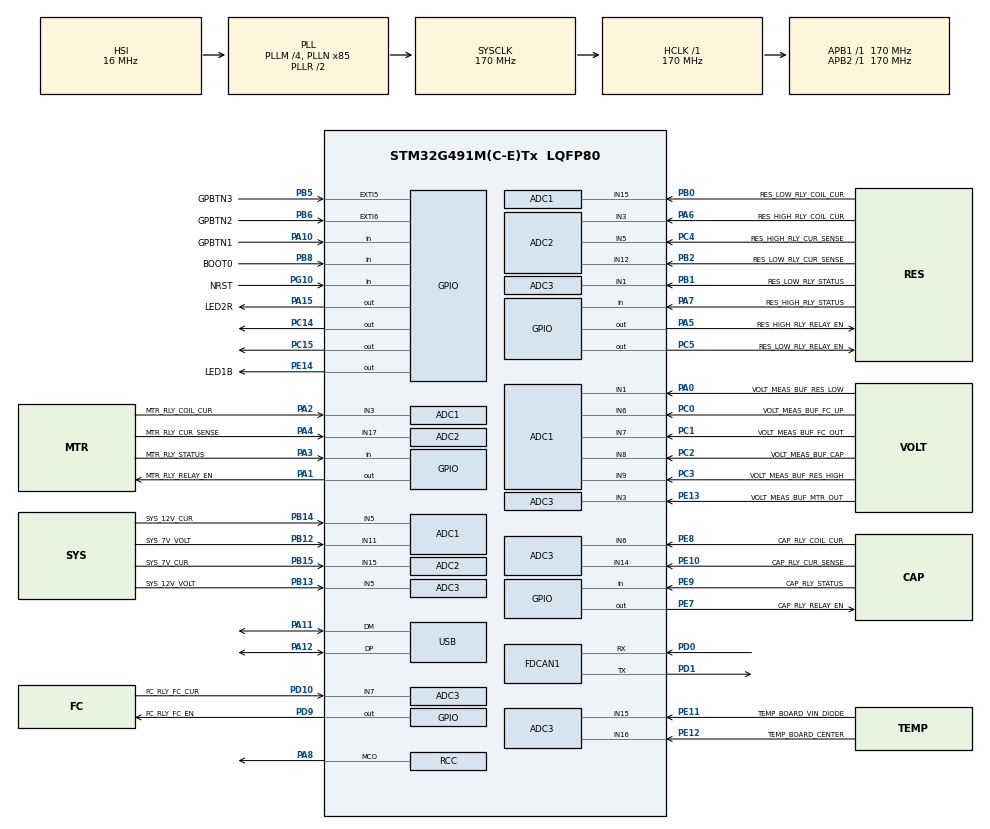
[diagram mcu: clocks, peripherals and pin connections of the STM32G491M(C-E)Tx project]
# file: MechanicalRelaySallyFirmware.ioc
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ADC1.Channel-0\#ChannelRegularConversion=ADC_CHANNEL_3
ADC1.NbrOfConversionFlag=1
ADC1.OffsetNumber-0\#ChannelRegularConversion=ADC_OFFSET_NONE
ADC1.Rank-0\#ChannelRegularConversion=1
ADC1.SamplingTime-0\#ChannelRegularConversion=ADC_SAMPLETIME_2CYCLES_5
ADC1.master=1
ADC2.Channel-0\#ChannelRegularConversion=ADC_CHANNEL_17
ADC2.NbrOfConversionFlag=1
ADC2.OffsetNumber-0\#ChannelRegularConversion=ADC_OFFSET_NONE
ADC2.Rank-0\#ChannelRegularConversion=1
ADC2.SamplingTime-0\#ChannelRegularConversion=ADC_SAMPLETIME_2CYCLES_5
ADC3.Channel-0\#ChannelRegularConversion=ADC_CHANNEL_1
ADC3.NbrOfConversionFlag=1
ADC3.OffsetNumber-0\#ChannelRegularConversion=ADC_OFFSET_NONE
ADC3.Rank-0\#ChannelRegularConversion=1
ADC3.SamplingTime-0\#ChannelRegularConversion=ADC_SAMPLETIME_2CYCLES_5
ADC3.master=1
FDCAN1.CalculateBaudRateNominal=3541666
FDCAN1.CalculateTimeBitNominal=282
FDCAN1.CalculateTimeQuantumNominal=94.11764705882354
Mcu.Family=STM32G4
Mcu.Name=STM32G491M(C-E)Tx
Mcu.Package=LQFP80
NVIC.PriorityGroup=NVIC_PRIORITYGROUP_4
NVIC.TIM7_IRQn=true\:15\:0\:false\:false\:true\:false\:true\:true
NVIC.TimeBase=TIM7_IRQn
NVIC.TimeBaseIP=TIM7
PA0.GPIO_Label=VOLT_MEAS_BUF_RES_LOW
PA0.Mode=IN1-Single-Ended
PA0.Signal=ADC1_IN1
PA1.GPIO_Label=MTR_RLY_RELAY_EN
PA1.Signal=GPIO_Output
PA10.GPIO_Label=GPBTN1
PA10.Signal=GPIO_Input
PA11.Mode=Device
PA11.Signal=USB_DM
PA12.Mode=Device
PA12.Signal=USB_DP
PA13.Mode=Serial_Wire
PA13.Signal=SYS_JTMS-SWDIO
PA14.Mode=Serial_Wire
PA14.Signal=SYS_JTCK-SWCLK
PA15.GPIO_Label=LED2R
PA15.Signal=GPIO_Output
PA2.GPIO_Label=MTR_RLY_COIL_CUR
PA2.Mode=IN3-Single-Ended
PA2.Signal=ADC1_IN3
PA3.GPIO_Label=MTR_RLY_STATUS
PA3.Signal=GPIO_Input
PA4.GPIO_Label=MTR_RLY_CUR_SENSE
PA4.Mode=IN17-Single-Ended
PA4.Signal=ADC2_IN17
PA5.GPIO_Label=RES_HIGH_RLY_RELAY_EN
PA5.Signal=GPIO_Output
PA6.GPIO_Label=RES_HIGH_RLY_COIL_CUR
PA6.Mode=IN3-Single-Ended
PA6.Signal=ADC2_IN3
PA7.GPIO_Label=RES_HIGH_RLY_STATUS
PA7.Signal=GPIO_Input
PA8.Mode=Clock-out
PA8.Signal=RCC_MCO
PB0.GPIO_Label=RES_LOW_RLY_COIL_CUR
PB0.Mode=IN15-Single-Ended
PB0.Signal=ADC1_IN15
PB1.GPIO_Label=RES_LOW_RLY_STATUS
PB1.Mode=IN1-Single-Ended
PB1.Signal=ADC3_IN1
PB12.GPIO_Label=SYS_7V_VOLT
PB12.Mode=IN11-Single-Ended
PB12.Signal=ADC1_IN11
PB13.GPIO_Label=SYS_12V_VOLT
PB13.Mode=IN5-Single-Ended
PB13.Signal=ADC3_IN5
PB14.GPIO_Label=SYS_12V_CUR
PB14.Mode=IN5-Single-Ended
PB14.Signal=ADC1_IN5
PB15.GPIO_Label=SYS_7V_CUR
PB15.Mode=IN15-Single-Ended
PB15.Signal=ADC2_IN15
PB2.GPIO_Label=RES_LOW_RLY_CUR_SENSE
PB2.Mode=IN12-Single-Ended
PB2.Signal=ADC2_IN12
PB5.GPIO_Label=GPBTN3
PB5.Signal=GPXTI5
PB6.GPIO_Label=GPBTN2
PB6.Signal=GPXTI6
PB8-BOOT0.GPIO_Label=BOOT0
PB8-BOOT0.Signal=GPIO_Input
PC0.GPIO_Label=VOLT_MEAS_BUF_FC_UP
PC0.Mode=IN6-Single-Ended
PC0.Signal=ADC1_IN6
PC1.GPIO_Label=VOLT_MEAS_BUF_FC_OUT
PC1.Mode=IN7-Single-Ended
PC1.Signal=ADC1_IN7
PC14-OSC32_IN.Signal=GPIO_Output
PC15-OSC32_OUT.Signal=GPIO_Output
PC2.GPIO_Label=VOLT_MEAS_BUF_CAP
PC2.Mode=IN8-Single-Ended
PC2.Signal=ADC1_IN8
PC3.GPIO_Label=VOLT_MEAS_BUF_RES_HIGH
PC3.Mode=IN9-Single-Ended
PC3.Signal=ADC1_IN9
PC4.GPIO_Label=RES_HIGH_RLY_CUR_SENSE
PC4.Mode=IN5-Single-Ended
PC4.Signal=ADC2_IN5
PC5.GPIO_Label=RES_LOW_RLY_RELAY_EN
PC5.Signal=GPIO_Output
PD0.Mode=FDCAN_Activate
PD0.Signal=FDCAN1_RX
PD1.Mode=FDCAN_Activate
PD1.Signal=FDCAN1_TX
PD10.GPIO_Label=FC_RLY_FC_CUR
PD10.Mode=IN7-Single-Ended
PD10.Signal=ADC3_IN7
PD9.GPIO_Label=FC_RLY_FC_EN
PD9.Signal=GPIO_Output
PE10.GPIO_Label=CAP_RLY_CUR_SENSE
PE10.Mode=IN14-Single-Ended
PE10.Signal=ADC3_IN14
PE11.GPIO_Label=TEMP_BOARD_VIN_DIODE
PE11.Mode=IN15-Single-Ended
PE11.Signal=ADC3_IN15
PE12.GPIO_Label=TEMP_BOARD_CENTER
PE12.Mode=IN16-Single-Ended
PE12.Signal=ADC3_IN16
PE13.GPIO_Label=VOLT_MEAS_BUF_MTR_OUT
PE13.Mode=IN3-Single-Ended
PE13.Signal=ADC3_IN3
PE14.GPIO_Label=LED1B
PE14.Signal=GPIO_Output
PE7.GPIO_Label=CAP_RLY_RELAY_EN
PE7.Signal=GPIO_Output
PE8.GPIO_Label=CAP_RLY_COIL_CUR
PE8.Mode=IN6-Single-Ended
PE8.Signal=ADC3_IN6
PE9.GPIO_Label=CAP_RLY_STATUS
PE9.Signal=GPIO_Input
PF0-OSC_IN.Mode=HSE-External-Clock-Source
PF0-OSC_IN.Signal=RCC_OSC_IN
PG10-NRST.GPIO_Label=NRST
PG10-NRST.Signal=GPIO_Input
ProjectManager.HeapSize=0x200
ProjectManager.StackSize=0x400
ProjectManager.TargetToolchain=STM32CubeIDE
RCC.ADC12Freq_Value=170000000
RCC.ADC345Freq_Value=170000000
RCC.AHBFreq_Value=170000000
RCC.APB1Freq_Value=170000000
RCC.APB1TimFreq_Value=170000000
RCC.APB2Freq_Value=170000000
RCC.APB2TimFreq_Value=170000000
RCC.CortexFreq_Value=170000000
RCC.EXTERNAL_CLOCK_VALUE=12288000
RCC.HCLKFreq_Value=170000000
RCC.HSE_VALUE=8000000
RCC.HSI48_VALUE=48000000
RCC.HSI_VALUE=16000000
RCC.LSE_VALUE=32768
RCC.PLLM=RCC_PLLM_DIV4
RCC.PLLN=85
RCC.RCC_MCO1Source=RCC_MCO1SOURCE_HSE
RCC.RCC_MCODiv=RCC_MCODIV_16
RCC.SYSCLKFreq_VALUE=170000000
RCC.SYSCLKSource=RCC_SYSCLKSOURCE_PLLCLK
RCC.VCOOutputFreq_Value=340000000
VP_ADC1_TempSens_Input.Mode=IN-TempSens
VP_ADC3_Vbat_Input.Mode=IN-Vbat
VP_ADC3_Vref_Input.Mode=IN-Vrefint
VP_SYS_VS_DBSignals.Mode=DisableDeadBatterySignals
VP_SYS_VS_tim7.Mode=TIM7
board=custom

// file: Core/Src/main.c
/* USER CODE BEGIN Header */
/**
 ******************************************************************************
 * @file           : main.c
 * @brief          : Main program body
 ******************************************************************************
 * @attention
 *
 * Copyright (c) 2025 STMicroelectronics.
 * All rights reserved.
 *
 * This software is licensed under terms that can be found in the LICENSE file
 * in the root directory of this software component.
 * If no LICENSE file comes with this software, it is provided AS-IS.
 *
 ******************************************************************************
 */
/* USER CODE END Header */
#include "main.h"
#include "adc.h"
#include "fdcan.h"
#include "usb.h"
#include "gpio.h"

void SystemClock_Config(void);

int main(void) {

	/* MCU Configuration--------------------------------------------------------*/

	/* Reset of all peripherals, Initializes the Flash interface and the Systick. */
	HAL_Init();

	/* Configure the system clock */
	SystemClock_Config();

	/* Initialize all configured peripherals */
	MX_GPIO_Init();
	MX_FDCAN1_Init();
	MX_ADC1_Init();
	MX_ADC2_Init();
	MX_ADC3_Init();
	MX_USB_PCD_Init();

	/* Infinite loop */
	while (1) {

		/* USER CODE BEGIN 3 */
		HAL_GPIO_TogglePin(RES_LOW_RLY_RELAY_EN_GPIO_Port,
				RES_LOW_RLY_RELAY_EN_Pin);
		HAL_Delay(1000);
	}
	/* USER CODE END 3 */
}

void SystemClock_Config(void) {
	RCC_OscInitTypeDef RCC_OscInitStruct = { 0 };
	RCC_ClkInitTypeDef RCC_ClkInitStruct = { 0 };

	/** Configure the main internal regulator output voltage
	 */
	HAL_PWREx_ControlVoltageScaling(PWR_REGULATOR_VOLTAGE_SCALE1_BOOST);

	/** Initializes the RCC Oscillators according to the specified parameters
	 * in the RCC_OscInitTypeDef structure.
	 */
	RCC_OscInitStruct.OscillatorType = RCC_OSCILLATORTYPE_HSI
			| RCC_OSCILLATORTYPE_HSI48 | RCC_OSCILLATORTYPE_HSE;
	RCC_OscInitStruct.HSEState = RCC_HSE_BYPASS;
	RCC_OscInitStruct.HSIState = RCC_HSI_ON;
	RCC_OscInitStruct.HSICalibrationValue = RCC_HSICALIBRATION_DEFAULT;
	RCC_OscInitStruct.HSI48State = RCC_HSI48_ON;
	RCC_OscInitStruct.PLL.PLLState = RCC_PLL_ON;
	RCC_OscInitStruct.PLL.PLLSource = RCC_PLLSOURCE_HSI;
	RCC_OscInitStruct.PLL.PLLM = RCC_PLLM_DIV4;
	RCC_OscInitStruct.PLL.PLLN = 85;
	RCC_OscInitStruct.PLL.PLLP = RCC_PLLP_DIV2;
	RCC_OscInitStruct.PLL.PLLQ = RCC_PLLQ_DIV2;
	RCC_OscInitStruct.PLL.PLLR = RCC_PLLR_DIV2;
	if (HAL_RCC_OscConfig(&RCC_OscInitStruct) != HAL_OK) {
		Error_Handler();
	}

	/** Initializes the CPU, AHB and APB buses clocks
	 */
	RCC_ClkInitStruct.ClockType = RCC_CLOCKTYPE_HCLK | RCC_CLOCKTYPE_SYSCLK
			| RCC_CLOCKTYPE_PCLK1 | RCC_CLOCKTYPE_PCLK2;
	RCC_ClkInitStruct.SYSCLKSource = RCC_SYSCLKSOURCE_PLLCLK;
	RCC_ClkInitStruct.AHBCLKDivider = RCC_SYSCLK_DIV1;
	RCC_ClkInitStruct.APB1CLKDivider = RCC_HCLK_DIV1;
	RCC_ClkInitStruct.APB2CLKDivider = RCC_HCLK_DIV1;

	if (HAL_RCC_ClockConfig(&RCC_ClkInitStruct, FLASH_LATENCY_4) != HAL_OK) {
		Error_Handler();
	}
	HAL_RCC_MCOConfig(RCC_MCO1, RCC_MCO1SOURCE_HSE, RCC_MCODIV_16);
}

void HAL_TIM_PeriodElapsedCallback(TIM_HandleTypeDef *htim) {
	if (htim->Instance == TIM7) {
		HAL_IncTick();
	}
}

void Error_Handler(void) {
	__disable_irq();
	while (1) {
	}
}
